# ATmega16HVA device description
Architecture: AVR8; Family: megaAVR
Registers are 8-bit, access not given, no defined reset value unless marked. A register's access mark holds for its fields unless they carry their own. Offsets are from the block's base; [hi:lo] are bit positions.

## WDT — Watchdog Timer
Instances: WDT 0x00
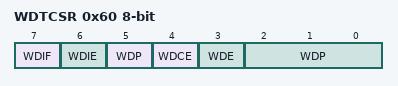
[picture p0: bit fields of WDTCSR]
0x60 WDTCSR — Watchdog Timer Control Register
  [7] WDIF — Watchdog Timeout Interrupt Flag
  [6] WDIE — Watchdog Timeout Interrupt Enable
  [4] WDCE — Watchdog Change Enable
  [3] WDE — Watch Dog Enable
  [5,2:0] WDP — Watchdog Timer Prescaler Bits
    0=Oscillator Cycles 2K; 1=Oscillator Cycles 4K; 2=Oscillator Cycles 8K; 3=Oscillator Cycles 16K; 4=Oscillator Cycles 32K; 5=Oscillator Cycles 64K; 6=Oscillator Cycles 128K; 7=Oscillator Cycles 256K; 8=Oscillator Cycles 512K; 9=Oscillator Cycles 1024K

## BANDGAP
Instances: BANDGAP 0x00
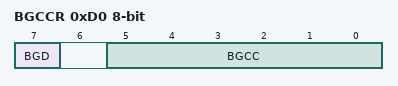
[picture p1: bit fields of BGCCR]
0xD0 BGCCR — Bandgap Calibration Register
  [7] BGD — Setting the BGD bit to one will disable the bandgap voltage reference. This bit must be cleared before enabling CC-ADC or V-ADC, and must remain unset while either ADC is enabled.
  [5:0] BGCC — BG Calibration of PTAT Current Bits
0xD1 BGCRR — Bandgap Calibration of Resistor Ladder
  [7:0] BGCR — Bandgap calibration bits

## EXINT — External Interrupts
Instances: EXINT 0x00
0x3C EIFR — External Interrupt Flag Register
  [2:0] INTF — External Interrupt Flags
0x3D EIMSK — External Interrupt Mask Register
  [2:0] INT — External Interrupt Request 2 Enable
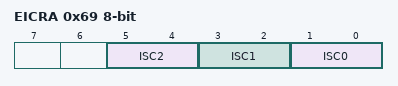
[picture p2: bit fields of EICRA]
0x69 EICRA — External Interrupt Control Register
  [all] fields
    0=Low Level of INTX; 1=Any Logical Change of INTX; 2=Falling Edge of INTX; 3=Rising Edge of INTX
  [5:4] ISC2 — External Interrupt Sense Control 2 Bits
  [3:2] ISC1 — External Interrupt Sense Control 1 Bits
  [1:0] ISC0 — External Interrupt Sense Control 0 Bits

## PORTC — I/O Port
Instances: PORTC 0x00
0x26 PINC bits used 0 — Port C Input Pins
0x28 PORTC bits used 0 — Port C Data Register

## PORTA — I/O Port
Instances: PORTA 0x00
0x20 PINA bits used 1:0 — Port A Input Pins
0x21 DDRA bits used 1:0 — Port A Data Direction Register
0x22 PORTA bits used 1:0 — Port A Data Register

## PORTB — I/O Port
Instances: PORTB 0x00
0x23 PINB bits used 3:0 — Input Pins, Port B
0x24 DDRB bits used 3:0 — Data Direction Register, Port B
0x25 PORTB bits used 3:0 — Data Register, Port B

## FET — FET Control
Instances: FET 0x00
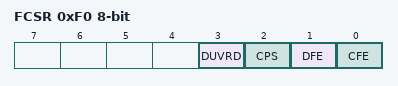
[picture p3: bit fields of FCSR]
0xF0 FCSR — FET Control and Status Register
  [3] DUVRD — Deep Under-Voltage Recovery Disable
  [2] CPS — Current Protection Status
  [1] DFE — Discharge FET Enable
  [0] CFE — Charge FET Enable

## SPI — Serial Peripheral Interface
Instances: SPI 0x00
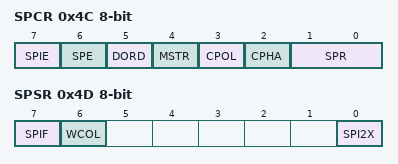
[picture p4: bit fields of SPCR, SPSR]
0x4C SPCR — SPI Control Register
  [7] SPIE — SPI Interrupt Enable
  [6] SPE — SPI Enable
  [5] DORD — Data Order
  [4] MSTR — Master/Slave Select
  [3] CPOL — Clock polarity
  [2] CPHA — Clock Phase
  [1:0] SPR — SPI Clock Rate Selects
    0=fosc/4; 1=fosc/16; 2=fosc/64; 3=fosc/128; 4=fosc/2; 5=fosc/8; 6=fosc/32; 7=fosc/64
0x4D SPSR — SPI Status Register
  [7] SPIF — SPI Interrupt Flag
  [6] WCOL — Write Collision Flag
  [0] SPI2X — Double SPI Speed Bit
0x4E SPDR — SPI Data Register

## BOOT_LOAD — Bootloader
Instances: BOOT_LOAD 0x00
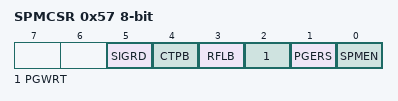
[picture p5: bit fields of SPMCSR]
0x57 SPMCSR — Store Program Memory Control and Status Register
  [5] SIGRD — Signature Row Read
  [4] CTPB — Clear Temporary Page Buffer
  [3] RFLB — Read Fuse and Lock Bits
  [2] PGWRT — Page Write
  [1] PGERS — Page Erase
  [0] SPMEN — Store Program Memory Enable

## CPU — CPU Registers
Instances: CPU 0x00
Parameters: CORE_VERSION=V2E
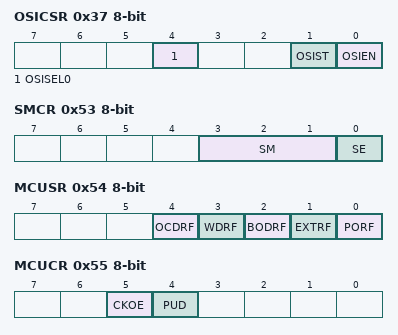
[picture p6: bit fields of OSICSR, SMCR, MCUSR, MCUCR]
0x37 OSICSR — Oscillator Sampling Interface Control and Status Register
  [4] OSISEL0 — Oscillator Sampling Interface Select 0
  [1] OSIST — Oscillator Sampling Interface Status
  [0] OSIEN — Oscillator Sampling Interface Enable
0x3E GPIOR0 — General Purpose IO Register 0
0x4A GPIOR1 — General Purpose IO Register 1
0x4B GPIOR2 — General Purpose IO Register 2
0x53 SMCR — Sleep Mode Control Register
  [3:1] SM — Sleep Mode Select bits
    0=IDLE; 1=ADC (ADC Noise Reduction (If Available)); 3=PSAVE (Power Save); 4=POFF (Power Off)
  [0] SE — Sleep Enable
0x54 MCUSR — MCU Status Register
  [4] OCDRF — OCD Reset Flag
  [3] WDRF — Watchdog Reset Flag
  [2] BODRF — Brown-out Reset Flag
  [1] EXTRF — External Reset Flag
  [0] PORF — Power-on reset flag
0x55 MCUCR — MCU Control Register
  [5] CKOE — Clock Output Enable
  [4] PUD — Pull-up disable
0x5D SP 16-bit bits used 9:0 — Stack Pointer
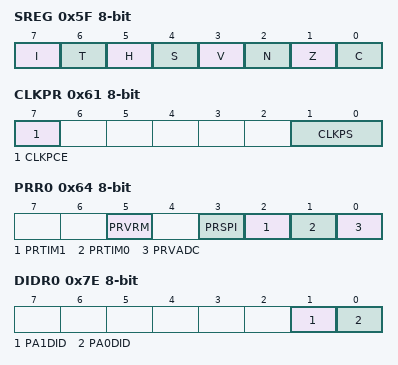
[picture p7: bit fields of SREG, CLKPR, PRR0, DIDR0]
0x5F SREG — Status Register
  [7] I — Global Interrupt Enable
  [6] T — Bit Copy Storage
  [5] H — Half Carry Flag
  [4] S — Sign Bit
  [3] V — Two's Complement Overflow Flag
  [2] N — Negative Flag
  [1] Z — Zero Flag
  [0] C — Carry Flag
0x61 CLKPR — Clock Prescale Register
  [7] CLKPCE — Clock Prescaler Change Enable
  [1:0] CLKPS — Clock Prescaler Select Bits
0x64 PRR0 — Power Reduction Register 0
  [5] PRVRM — Power Reduction Voltage Regulator Monitor
  [3] PRSPI — Power reduction SPI
  [2] PRTIM1 — Power Reduction Timer/Counter1
  [1] PRTIM0 — Power Reduction Timer/Counter0
  [0] PRVADC — Power Reduction V-ADC
0x66 FOSCCAL — Fast Oscillator Calibration Value
0x7E DIDR0 — Digital Input Disable Register
  [1] PA1DID — When this bit is written logic one, the digital input buffer of the corresponding V_ADC pin is disabled.
  [0] PA0DID — When this bit is written logic one, the digital input buffer of the corresponding V_ADC pin is disabled.
